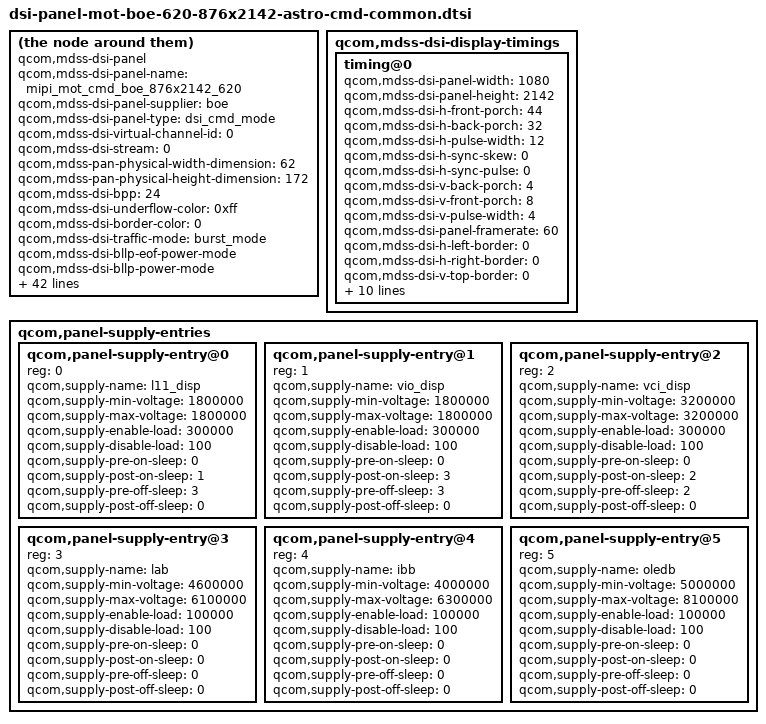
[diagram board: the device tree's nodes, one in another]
/* Copyright (c) 2019, The Linux Foundation. All rights reserved.
 *
 * This program is free software; you can redistribute it and/or modify
 * it under the terms of the GNU General Public License version 2 and
 * only version 2 as published by the Free Software Foundation.
 *
 * This program is distributed in the hope that it will be useful,
 * but WITHOUT ANY WARRANTY; without even the implied warranty of
 * MERCHANTABILITY or FITNESS FOR A PARTICULAR PURPOSE.  See the
 * GNU General Public License for more details.
 */

compatible = "qcom,mdss-dsi-panel";
qcom,mdss-dsi-panel-name = "mipi_mot_cmd_boe_876x2142_620";
qcom,mdss-dsi-panel-supplier = "boe";
qcom,mdss-dsi-panel-type = "dsi_cmd_mode";
qcom,mdss-dsi-virtual-channel-id = <0>;
qcom,mdss-dsi-stream = <0>;
qcom,mdss-pan-physical-width-dimension = <62>;
qcom,mdss-pan-physical-height-dimension = <172>;
qcom,mdss-dsi-bpp = <24>;
qcom,mdss-dsi-underflow-color = <0xff>;
qcom,mdss-dsi-border-color = <0>;

qcom,mdss-dsi-traffic-mode = "burst_mode";
qcom,mdss-dsi-bllp-eof-power-mode;
qcom,mdss-dsi-bllp-power-mode;
qcom,mdss-dsi-lane-0-state;
qcom,mdss-dsi-lane-1-state;
qcom,mdss-dsi-lane-2-state;
qcom,mdss-dsi-lane-3-state;

qcom,mdss-dsi-dma-trigger = "trigger_sw";
qcom,mdss-dsi-mdp-trigger = "none";
qcom,mdss-dsi-reset-sequence = <0 11>, <1 1>, <0 1>, <1 21>;
qcom,mdss-dsi-lp11-init;
qcom,mdss-dsi-tx-eot-append;

qcom,mdss-dsi-te-pin-select = <1>;
qcom,mdss-dsi-te-dcs-command = <1>;
qcom,mdss-dsi-te-check-enable;
qcom,mdss-dsi-te-using-te-pin;

qcom,bklt-dcs-2bytes-enabled;
qcom,mdss-dsi-bl-min-level = <3>;
qcom,mdss-dsi-bl-max-level = <3450>;
qcom,mdss-dsi-bl-pmic-control-type = "bl_ctrl_dcs";

qcom,mdss-dsi-panel-hdr-enabled;
qcom,mdss-dsi-panel-hdr-color-primaries = <14800 15350 33200 16500
	13350 33950 7550 3000>;

qcom,mdss-dsi-panel-peak-brightness = <4260000>;
qcom,mdss-dsi-panel-blackness-level = <18>;

/* Enable ESD checking */
qcom,esd-check-enabled;
qcom,mdss-dsi-panel-status-check-mode = "reg_read";
qcom,mdss-dsi-panel-status-read-length = <1>;
qcom,mdss-dsi-panel-status-command = [06 01 00 01 00 00 01 0A];
qcom,mdss-dsi-panel-status-command-state = "dsi_hs_mode";
qcom,mdss-dsi-panel-status-value = <0x9c>;

/* MOT panel params */
qcom,mdss-dsi-hbm-on-command = [39 01 00 00 00 00 03 51 0F FF];
qcom,mdss-dsi-hbm-off-command = [39 01 00 00 00 00 03 51 0B 95];
qcom,mdss-dsi-acl-on-command = [15 01 00 00 00 00 02 55 03];
qcom,mdss-dsi-acl-off-command = [15 01 00 00 00 00 02 55 00];

qcom,mdss-dsi-panel-hbm-is-51cmd;

qcom,mdss-dsi-display-timings {
	timing@0{
		qcom,mdss-dsi-panel-width = <1080>;
		qcom,mdss-dsi-panel-height = <2142>;
		qcom,mdss-dsi-h-front-porch = <44>;
		qcom,mdss-dsi-h-back-porch = <32>;
		qcom,mdss-dsi-h-pulse-width = <12>;
		qcom,mdss-dsi-h-sync-skew = <0>;
		qcom,mdss-dsi-h-sync-pulse = <0>;
		qcom,mdss-dsi-v-back-porch = <4>;
		qcom,mdss-dsi-v-front-porch = <8>;
		qcom,mdss-dsi-v-pulse-width = <4>;
		qcom,mdss-dsi-panel-framerate = <60>;
		qcom,mdss-dsi-h-left-border = <0>;
		qcom,mdss-dsi-h-right-border = <0>;
		qcom,mdss-dsi-v-top-border = <0>;
		qcom,mdss-dsi-v-bottom-border = <0>;
		qcom,mdss-dsi-panel-jitter = <0x20 0xa>;

		qcom,mdss-dsi-on-command = [
			15 00 00 00 00 00 02 FE D0
			15 00 00 00 00 00 02 99 00
			15 00 00 00 00 00 02 FE 40
			15 00 00 00 00 00 02 9A 00
			15 00 00 00 00 00 02 FE 00
			15 00 00 00 00 00 02 35 00
			15 00 00 00 00 00 02 5E 01
			15 00 00 00 00 00 02 C2 08
			15 00 00 00 00 00 02 53 20 /*HBM off ,dimming=1frame*/
			15 00 00 00 00 00 02 55 00	/*ACL OFF */
			39 00 00 00 00 00 03 51 00 00
			05 01 00 00 78 00 01 11
			05 01 00 00 00 00 01 29];	/* display on */
		qcom,mdss-dsi-off-command = [
			05 01 00 00 23 00 01 28		/* display_off */
			05 01 00 00 78 00 01 10];	/* enter sleep mode */

		qcom,mdss-dsi-on-command-state = "dsi_lp_mode";
		qcom,mdss-dsi-off-command-state = "dsi_lp_mode";
		qcom,mdss-dsi-force-tx-mode = "dsi_hs_mode";

		qcom,mdss-dsi-panel-clockrate = <1102000000>;

	};
};

qcom,panel-supply-entries {
	#address-cells = <1>;
	#size-cells = <0>;

	qcom,panel-supply-entry@0 {
		reg = <0>;
		qcom,supply-name = "l11_disp";
		qcom,supply-min-voltage = <1800000>;
		qcom,supply-max-voltage = <1800000>;
		qcom,supply-enable-load = <300000>;
		qcom,supply-disable-load = <100>;
		qcom,supply-pre-on-sleep = <0>;
		qcom,supply-post-on-sleep = <1>;
		qcom,supply-pre-off-sleep = <3>;
		qcom,supply-post-off-sleep = <0>;
	};

	qcom,panel-supply-entry@1 {
		reg = <1>;
		qcom,supply-name = "vio_disp";
		qcom,supply-min-voltage = <1800000>;
		qcom,supply-max-voltage = <1800000>;
		qcom,supply-enable-load = <300000>;
		qcom,supply-disable-load = <100>;
		qcom,supply-pre-on-sleep = <0>;
		qcom,supply-post-on-sleep = <3>;
		qcom,supply-pre-off-sleep = <3>;
		qcom,supply-post-off-sleep = <0>;
	};

	qcom,panel-supply-entry@2 {
		reg = <2>;
		qcom,supply-name = "vci_disp";
		qcom,supply-min-voltage = <3200000>;
		qcom,supply-max-voltage = <3200000>;
		qcom,supply-enable-load = <300000>;
		qcom,supply-disable-load = <100>;
		qcom,supply-pre-on-sleep = <0>;
		qcom,supply-post-on-sleep = <2>;
		qcom,supply-pre-off-sleep = <2>;
		qcom,supply-post-off-sleep = <0>;
	};

	qcom,panel-supply-entry@3 {
		reg = <3>;
		qcom,supply-name = "lab";
		qcom,supply-min-voltage = <4600000>;
		qcom,supply-max-voltage = <6100000>;
		qcom,supply-enable-load = <100000>;
		qcom,supply-disable-load = <100>;
		qcom,supply-pre-on-sleep = <0>;
		qcom,supply-post-on-sleep = <0>;
		qcom,supply-pre-off-sleep = <0>;
		qcom,supply-post-off-sleep = <0>;
	};

	qcom,panel-supply-entry@4 {
		reg = <4>;
		qcom,supply-name = "ibb";
		qcom,supply-min-voltage = <4000000>;
		qcom,supply-max-voltage = <6300000>;
		qcom,supply-enable-load = <100000>;
		qcom,supply-disable-load = <100>;
		qcom,supply-pre-on-sleep = <0>;
		qcom,supply-post-on-sleep = <0>;
		qcom,supply-pre-off-sleep = <0>;
		qcom,supply-post-off-sleep = <0>;
	};

	qcom,panel-supply-entry@5 {
		reg = <5>;
		qcom,supply-name = "oledb";
		qcom,supply-min-voltage = <5000000>;
		qcom,supply-max-voltage = <8100000>;
		qcom,supply-enable-load = <100000>;
		qcom,supply-disable-load = <100>;
		qcom,supply-pre-on-sleep = <0>;
		qcom,supply-post-on-sleep = <0>;
		qcom,supply-pre-off-sleep = <0>;
		qcom,supply-post-off-sleep = <0>;
	};
};
